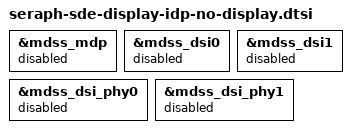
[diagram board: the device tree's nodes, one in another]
// SPDX-License-Identifier: BSD-3-Clause
/*
 * Copyright (c) Qualcomm Technologies, Inc. and/or its subsidiaries.
 */

&mdss_mdp {
	status = "disabled";
};

&mdss_dsi0 {
	status = "disabled";
};

&mdss_dsi1 {
	status = "disabled";
};

&mdss_dsi_phy0 {
	status = "disabled";
};

&mdss_dsi_phy1 {
	status = "disabled";
};
